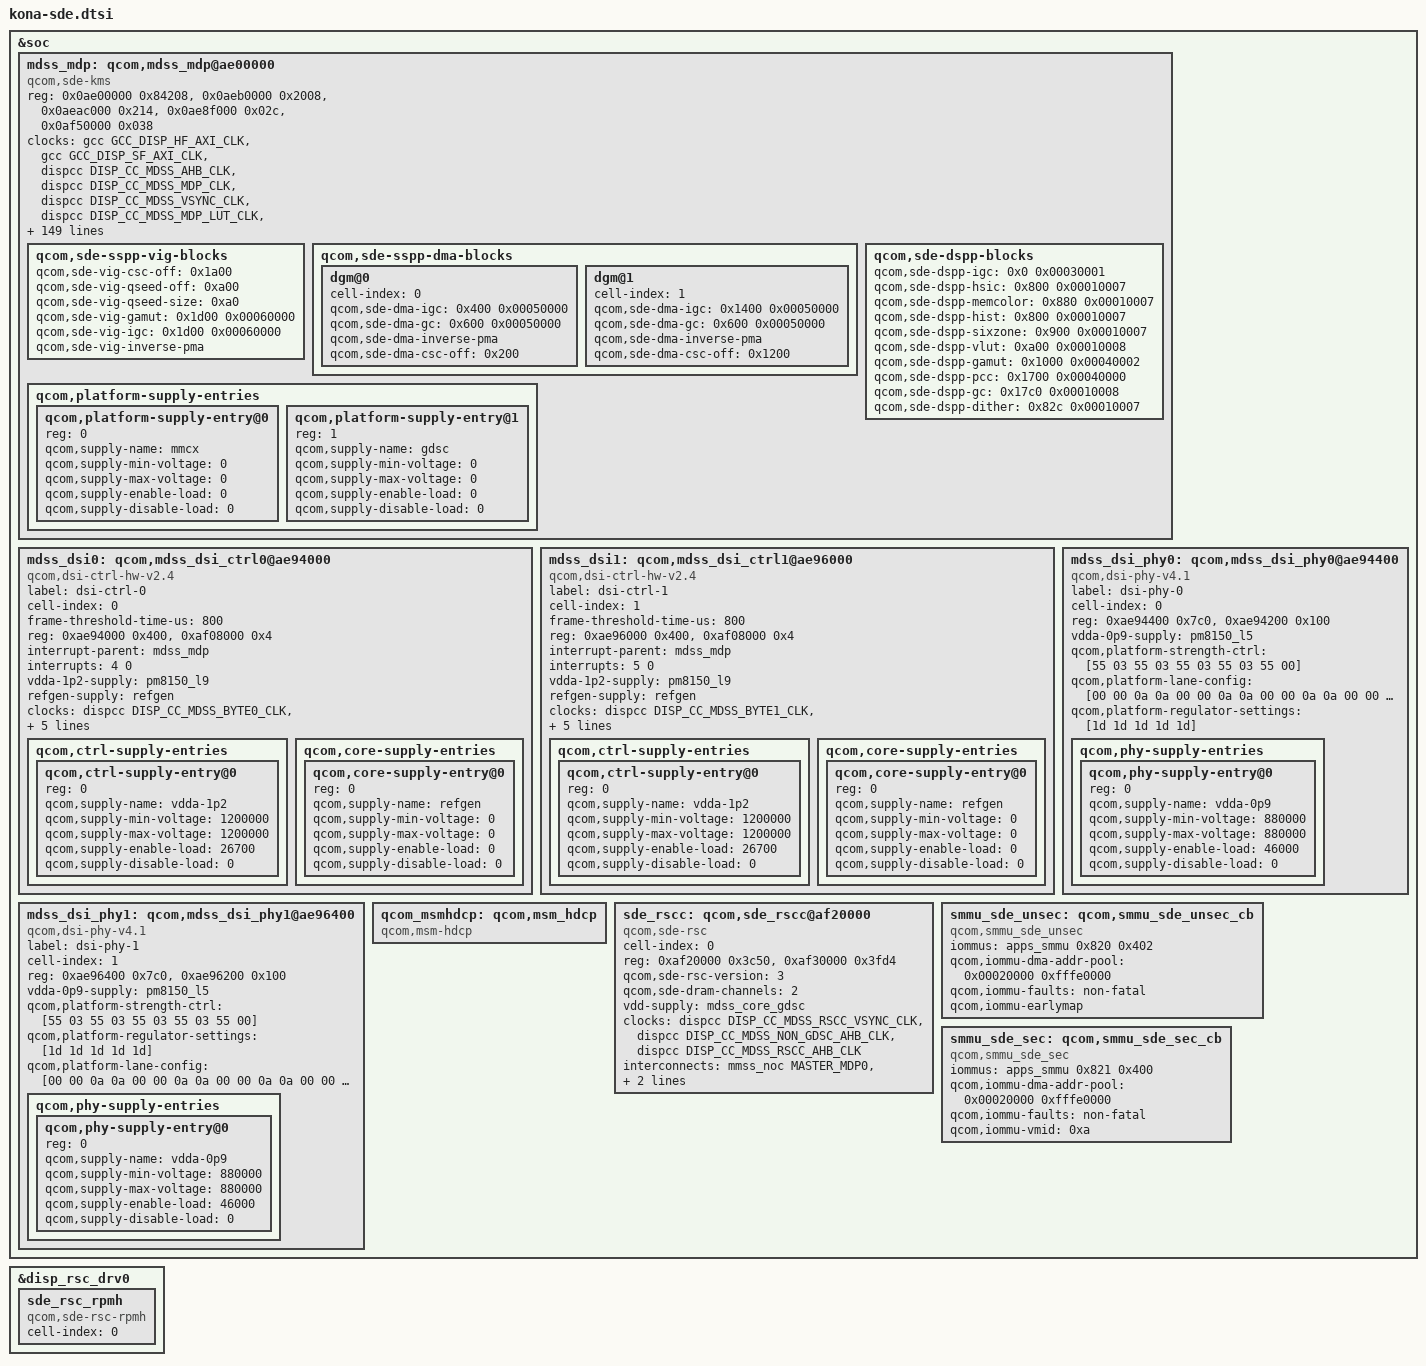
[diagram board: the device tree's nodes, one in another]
// SPDX-License-Identifier: GPL-2.0-only
/*
 * Kona (SM8250) MDSS/SDE controller nodes for the msm-5.15 display
 * techpack.  Hardware values (register offsets/sizes, block topology,
 * xin-ids, ...) are carried over from the 4.19 LG kona tree; the
 * property *names* follow the msm-5.15 SDE bindings.
 *
 * qcom,sde-hw-version is set explicitly to SDE_HW_VER(6,0,0) (kona,
 * SDE 6.0.0) so the catalog picks the IS_KONA_TARGET branch instead of
 * relying on socinfo.
 */

#include <dt-bindings/clock/qcom,rpmh.h>
#include <dt-bindings/clock/qcom,gcc-sm8250.h>
#include <dt-bindings/clock/qcom,dispcc-sm8250.h>
#include <dt-bindings/interrupt-controller/irq.h>
#include <dt-bindings/interconnect/qcom,kona.h>
#include <dt-bindings/regulator/qcom,rpmh-regulator-levels.h>

&soc {
	mdss_mdp: qcom,mdss_mdp@ae00000 {
		compatible = "qcom,sde-kms";
		reg = <0x0ae00000 0x84208>,
		      <0x0aeb0000 0x2008>,
		      <0x0aeac000 0x214>,
		      <0x0ae8f000 0x02c>,
		      <0x0af50000 0x038>;
		reg-names = "mdp_phys",
			"vbif_phys",
			"regdma_phys",
			"sid_phys",
			"swfuse_phys";

		/*
		 * msm-5.15 gcc-sm8250 no longer registers GCC_DISP_AHB_CLK;
		 * gcc_sm8250_probe() force-enables that branch in hardware and
		 * the clock is not exposed to consumers.  The 4.19 "gcc_iface"
		 * entry therefore has no handle in 5.15 and made
		 * sde_power_resource_init() fail with "clock set rate failed".
		 * The HF/SF AXI branches still exist.
		 */
		clocks =
			<&gcc GCC_DISP_HF_AXI_CLK>,
			<&gcc GCC_DISP_SF_AXI_CLK>,
			<&dispcc DISP_CC_MDSS_AHB_CLK>,
			<&dispcc DISP_CC_MDSS_MDP_CLK>,
			<&dispcc DISP_CC_MDSS_VSYNC_CLK>,
			<&dispcc DISP_CC_MDSS_MDP_LUT_CLK>,
			<&dispcc DISP_CC_MDSS_ROT_CLK>;
		clock-names = "gcc_bus", "gcc_nrt_bus",
				"iface_clk", "core_clk", "vsync_clk",
				"lut_clk", "rot_clk";
		clock-rate = <0 0 0 300000000 19200000 300000000 19200000>;
		clock-max-rate = <0 0 0 460000000 19200000 460000000
					460000000>;

		gdsc-supply = <&mdss_core_gdsc>;
		mmcx-supply = <&VDD_MMCX_LEVEL>;

		/* interrupt config */
		interrupts = <0 83 IRQ_TYPE_LEVEL_HIGH>;
		interrupt-controller;
		#interrupt-cells = <1>;
		/* msm-5.15 sde_connector_backlight_setup()/mi_disp expect a
		 * thermal cooling device on the mdss node; without this the
		 * backlight registration fails with -ENODEV and the DSI
		 * connector init is aborted.
		 */
		#cooling-cells = <2>;

		#address-cells = <1>;
		#size-cells = <0>;

		#power-domain-cells = <0>;

		/* hw blocks */
		qcom,sde-off = <0x1000>;
		qcom,sde-len = <0x494>;

		qcom,sde-hw-version = <0x60000000>;

		qcom,sde-ctl-off = <0x2000 0x2200 0x2400
				     0x2600 0x2800 0x2a00>;
		qcom,sde-ctl-size = <0x1dc>;
		qcom,sde-ctl-display-pref = "primary", "none", "none",
			    "none", "none";

		qcom,sde-mixer-off = <0x45000 0x46000 0x47000
				      0x48000 0x49000 0x4a000>;
		qcom,sde-mixer-size = <0x320>;
		qcom,sde-mixer-display-pref = "primary", "primary", "none",
					      "none", "none", "none";

		qcom,sde-mixer-cwb-pref = "none", "none", "cwb",
					      "cwb", "cwb", "cwb";

		qcom,sde-dspp-top-off = <0x1300>;
		qcom,sde-dspp-top-size = <0x80>;
		qcom,sde-dspp-off = <0x55000 0x57000 0x59000 0x5b000>;
		qcom,sde-dspp-size = <0x1800>;

		qcom,sde-dest-scaler-top-off = <0x00061000>;
		qcom,sde-dest-scaler-top-size = <0x1c>;
		qcom,sde-dest-scaler-off = <0x800 0x1000>;
		qcom,sde-dest-scaler-size = <0x800>;

		qcom,sde-wb-off = <0x66000>;
		qcom,sde-wb-size = <0x2c8>;
		qcom,sde-wb-xin-id = <6>;
		qcom,sde-wb-id = <2>;
		qcom,sde-wb-clk-ctrl = <0x2bc 16>;
		qcom,sde-wb-clk-status = <0x3bc 20>;

		qcom,sde-intf-off = <0x6b000 0x6b800
					0x6c000 0x6c800>;
		qcom,sde-intf-size = <0x2b8>;
		qcom,sde-intf-type = "dp", "dsi", "dsi", "dp";

		/*
		 * Tear-check interrupt blocks.  msm-4.19's kona catalog set
		 * SDE_INTF_TE unconditionally for hw 5.x/6.x and hardcoded
		 * these two offsets (MDP_INTF_TEAR_INTF_1/2_IRQ_OFF in
		 * sde_hw_interrupts.c), so command-mode panels got their
		 * rd_ptr/wr_ptr IRQs from the INTF tear block.  The 5.15
		 * catalog is DT-driven: without this property
		 * intf->te_irq_offset stays 0, SDE_INTF_TE is never set,
		 * phys_enc->has_intf_te = false, and cmd mode ends up
		 * polling the ping-pong block that kona does not implement
		 * as a tear source -> wr_ptr_irq/pingpong timeouts and no
		 * frame ever completes.  Index order follows
		 * qcom,sde-intf-type (dp, dsi, dsi, dp); 0 = no tear block.
		 */
		qcom,sde-intf-tear-irq-off = <0 0x6e800 0x6e900 0>;

		qcom,sde-pp-off = <0x71000 0x71800
					  0x72000 0x72800 0x73000 0x73800>;
		qcom,sde-pp-slave = <0x0 0x0 0x0 0x0 0x0 0x0>;
		qcom,sde-pp-size = <0xd4>;
		qcom,sde-pp-merge-3d-id = <0x0 0x0 0x1 0x1 0x2 0x2>;

		qcom,sde-merge-3d-off = <0x84000 0x84100 0x84200>;
		qcom,sde-merge-3d-size = <0x100>;

		qcom,sde-te2-off = <0x2000 0x2000 0x0 0x0 0x0 0x0>;

		qcom,sde-cdm-off = <0x7a200>;
		qcom,sde-cdm-size = <0x224>;

		qcom,sde-dsc-off = <0x81000 0x81400 0x81800 0x81c00>;
		qcom,sde-dsc-size = <0x140>;
		qcom,sde-dsc-pair-mask = <2 1 4 3>;
		qcom,sde-dsc-linewidth = <2048>;

		qcom,sde-dither-off = <0x30e0 0x30e0 0x30e0
							0x30e0 0x30e0 0x30e0>;
		qcom,sde-dither-version = <0x00010000>;
		qcom,sde-dither-size = <0x20>;

		qcom,sde-sspp-type = "vig", "vig", "vig", "vig",
					"dma", "dma", "dma", "dma";

		qcom,sde-sspp-off = <0x5000 0x7000 0x9000 0xb000
					0x25000 0x27000 0x29000 0x2b000>;
		qcom,sde-sspp-src-size = <0x1f8>;

		qcom,sde-sspp-xin-id = <0 4 8 12
					1 5 9 13>;
		qcom,sde-sspp-excl-rect = <1 1 1 1
						1 1 1 1>;
		qcom,sde-sspp-smart-dma-priority = <5 6 7 8 1 2 3 4>;
		qcom,sde-smart-dma-rev = "smart_dma_v2p5";

		qcom,sde-mixer-pair-mask = <2 1 4 3 6 5>;

		qcom,sde-mixer-blend-op-off = <0x20 0x38 0x50 0x68 0x80 0x98
						0xb0 0xc8 0xe0 0xf8 0x110>;

		qcom,sde-max-per-pipe-bw-kbps = <4400000 4400000
						 4400000 4400000
						 4400000 4400000
						 4400000 4400000>;

		qcom,sde-max-per-pipe-bw-high-kbps = <5300000 5300000
						      5300000 5300000
						      5300000 5300000
						      5300000 5300000>;

		/* offsets are relative to "mdp_phys + qcom,sde-off */
		qcom,sde-sspp-clk-ctrl =
				<0x2ac 0>, <0x2b4 0>, <0x2bc 0>, <0x2c4 0>,
				 <0x2ac 8>, <0x2b4 8>, <0x2bc 8>, <0x2c4 8>;
		qcom,sde-sspp-csc-off = <0x1a00>;
		qcom,sde-csc-type = "csc-10bit";
		qcom,sde-qseed-sw-lib-rev = "qseedv3lite";
		qcom,sde-qseed-scalar-version = <0x3000>;
		qcom,sde-sspp-qseed-off = <0xa00>;
		qcom,sde-mixer-linewidth = <2560>;
		qcom,sde-sspp-linewidth = <4096>;
		qcom,sde-wb-linewidth = <4096>;
		qcom,sde-mixer-blendstages = <0xb>;
		qcom,sde-highest-bank-bit = <0x3>;
		qcom,sde-ubwc-version = <0x40000000>;
		qcom,sde-ubwc-swizzle = <0x6>;
		qcom,sde-ubwc-bw-calc-version = <0x1>;
		qcom,sde-ubwc-static = <0x1>;
		qcom,sde-macrotile-mode = <0x1>;
		qcom,sde-smart-panel-align-mode = <0xc>;
		qcom,sde-panic-per-pipe;
		qcom,sde-has-src-split;
		qcom,sde-pipe-order-version = <0x1>;
		qcom,sde-has-dim-layer;
		qcom,sde-has-dest-scaler;
		qcom,sde-has-idle-pc;
		qcom,sde-max-dest-scaler-input-linewidth = <2048>;
		qcom,sde-max-dest-scaler-output-linewidth = <2560>;
		qcom,sde-max-bw-low-kbps = <13700000>;
		qcom,sde-max-bw-high-kbps = <16600000>;
		qcom,sde-min-core-ib-kbps = <4800000>;
		qcom,sde-min-llcc-ib-kbps = <0>;
		qcom,sde-min-dram-ib-kbps = <800000>;
		qcom,sde-dspp-ltm-version = <0x00010000>;
		/* offsets are based off dspp 0 and dspp 1 */
		qcom,sde-dspp-ltm-off = <0x2a000 0x28100>;

		qcom,sde-uidle-off = <0x80000>;
		qcom,sde-uidle-size = <0x70>;

		qcom,sde-vbif-off = <0>;
		qcom,sde-vbif-size = <0x1040>;
		qcom,sde-vbif-id = <0>;
		qcom,sde-vbif-memtype-0 = <3 3 3 3 3 3 3 3>;
		qcom,sde-vbif-memtype-1 = <3 3 3 3 3 3>;

		qcom,sde-vbif-qos-rt-remap = <3 3 4 4 5 5 6 6>;
		qcom,sde-vbif-qos-nrt-remap = <3 3 3 3 3 3 3 3>;
		qcom,sde-vbif-qos-cwb-remap = <3 3 4 4 5 5 6 3>;
		qcom,sde-vbif-qos-lutdma-remap = <3 3 3 3 4 4 4 4>;

		qcom,sde-cdp-setting = <1 1>, <1 0>;

		qcom,sde-qos-cpu-mask = <0x3>;
		qcom,sde-qos-cpu-mask-performance = <0xf>;
		qcom,sde-qos-cpu-dma-latency = <300>;
		qcom,sde-qos-cpu-irq-latency = <300>;

		/* offsets are relative to "mdp_phys + qcom,sde-off */
		qcom,sde-reg-dma-off = <0>;
		qcom,sde-reg-dma-version = <0x00010002>;
		qcom,sde-reg-dma-trigger-off = <0x119c>;
		qcom,sde-reg-dma-xin-id = <7>;
		qcom,sde-reg-dma-clk-ctrl = <0x2bc 20>;

		qcom,sde-secure-sid-mask = <0x4000821>;

		/* data and reg bus scale settings */
		interconnects =
			<&mmss_noc MASTER_MDP0 &mc_virt SLAVE_EBI1>,
			<&mmss_noc MASTER_MDP1 &mc_virt SLAVE_EBI1>,
			<&gem_noc MASTER_APPSS_PROC
				&config_noc SLAVE_DISPLAY_CFG>;
		interconnect-names = "qcom,sde-data-bus0", "qcom,sde-data-bus1",
			"qcom,sde-reg-bus";

		qcom,sde-ib-bw-vote = <2500000 0 800000>;

		/*
		 * msm-5.15 still requires the legacy reg-bus vote table even
		 * though the reg bus itself is voted through interconnects.
		 * Values are kona's 4.19 mdss_reg table in (ab, ib) form:
		 * disabled / low / medium / high.
		 */
		qcom,sde-reg-bus,vectors-KBps = <0 0>,
				<0 76800>,
				<0 150000>,
				<0 300000>;

		qcom,sde-sspp-vig-blocks {
			qcom,sde-vig-csc-off = <0x1a00>;
			qcom,sde-vig-qseed-off = <0xa00>;
			qcom,sde-vig-qseed-size = <0xa0>;
			qcom,sde-vig-gamut = <0x1d00 0x00060000>;
			qcom,sde-vig-igc = <0x1d00 0x00060000>;
			qcom,sde-vig-inverse-pma;
		};

		qcom,sde-sspp-dma-blocks {
			dgm@0 {
				cell-index = <0>;
				qcom,sde-dma-igc = <0x400 0x00050000>;
				qcom,sde-dma-gc = <0x600 0x00050000>;
				qcom,sde-dma-inverse-pma;
				qcom,sde-dma-csc-off = <0x200>;
			};

			dgm@1 {
				cell-index = <1>;
				qcom,sde-dma-igc = <0x1400 0x00050000>;
				qcom,sde-dma-gc = <0x600 0x00050000>;
				qcom,sde-dma-inverse-pma;
				qcom,sde-dma-csc-off = <0x1200>;
			};
		};

		qcom,sde-dspp-blocks {
			qcom,sde-dspp-igc = <0x0 0x00030001>;
			qcom,sde-dspp-hsic = <0x800 0x00010007>;
			qcom,sde-dspp-memcolor = <0x880 0x00010007>;
			qcom,sde-dspp-hist = <0x800 0x00010007>;
			qcom,sde-dspp-sixzone= <0x900 0x00010007>;
			qcom,sde-dspp-vlut = <0xa00 0x00010008>;
			qcom,sde-dspp-gamut = <0x1000 0x00040002>;
			qcom,sde-dspp-pcc = <0x1700 0x00040000>;
			qcom,sde-dspp-gc = <0x17c0 0x00010008>;
			qcom,sde-dspp-dither = <0x82c 0x00010007>;
		};

		qcom,platform-supply-entries {
			#address-cells = <1>;
			#size-cells = <0>;

			qcom,platform-supply-entry@0 {
				reg = <0>;
				qcom,supply-name = "mmcx";
				qcom,supply-min-voltage = <0>;
				qcom,supply-max-voltage = <0>;
				qcom,supply-enable-load = <0>;
				qcom,supply-disable-load = <0>;
			};

			/*
			 * msm-5.15 gdsc-regulator registers mdss_core_gdsc as a
			 * regulator and relies on a proxy consumer that is torn
			 * down by late_initcall_sync(regulator_proxy_consumer_remove_all).
			 * The display power handle must therefore hold a real
			 * reference, otherwise the GDSC is powered off at the end
			 * of late init while the MDP is still scanning out the
			 * cont-splash frame (SMMU fault at iova 0).
			 *
			 * The entry is named "gdsc" (not "sde-vdd") because
			 * msm_dss_is_hw_controlled() special-cases exactly that
			 * name: once the display RSC has handed the GDSC over to
			 * its hardware trigger (REGULATOR_MODE_FAST) the MDP must
			 * not enable/disable it itself, otherwise gdsc_enable()
			 * fails with -EBUSY ("Invalid enable while ... is under HW
			 * control") and the failed power-up is followed by
			 * register writes to an unpowered MDP (SError panic).
			 */
			qcom,platform-supply-entry@1 {
				reg = <1>;
				qcom,supply-name = "gdsc";
				qcom,supply-min-voltage = <0>;
				qcom,supply-max-voltage = <0>;
				qcom,supply-enable-load = <0>;
				qcom,supply-disable-load = <0>;
			};
		};
	};

	mdss_dsi0: qcom,mdss_dsi_ctrl0@ae94000 {
		compatible = "qcom,dsi-ctrl-hw-v2.4";
		label = "dsi-ctrl-0";
		cell-index = <0>;
		frame-threshold-time-us = <800>;
		reg = <0xae94000 0x400>,
			<0xaf08000 0x4>;
		reg-names = "dsi_ctrl", "disp_cc_base";
		interrupt-parent = <&mdss_mdp>;
		interrupts = <4 0>;
		vdda-1p2-supply = <&pm8150_l9>;
		refgen-supply = <&refgen>;
		clocks = <&dispcc DISP_CC_MDSS_BYTE0_CLK>,
			<&dispcc DISP_CC_MDSS_BYTE0_CLK_SRC>,
			<&dispcc DISP_CC_MDSS_BYTE0_INTF_CLK>,
			<&dispcc DISP_CC_MDSS_PCLK0_CLK>,
			<&dispcc DISP_CC_MDSS_PCLK0_CLK_SRC>,
			<&dispcc DISP_CC_MDSS_ESC0_CLK>;
		clock-names = "byte_clk", "byte_clk_rcg", "byte_intf_clk",
				"pixel_clk", "pixel_clk_rcg", "esc_clk";

		qcom,ctrl-supply-entries {
			#address-cells = <1>;
			#size-cells = <0>;

			qcom,ctrl-supply-entry@0 {
				reg = <0>;
				qcom,supply-name = "vdda-1p2";
				qcom,supply-min-voltage = <1200000>;
				qcom,supply-max-voltage = <1200000>;
				qcom,supply-enable-load = <26700>;
				qcom,supply-disable-load = <0>;
			};
		};

		qcom,core-supply-entries {
			#address-cells = <1>;
			#size-cells = <0>;

			qcom,core-supply-entry@0 {
				reg = <0>;
				qcom,supply-name = "refgen";
				qcom,supply-min-voltage = <0>;
				qcom,supply-max-voltage = <0>;
				qcom,supply-enable-load = <0>;
				qcom,supply-disable-load = <0>;
			};
		};
	};

	mdss_dsi1: qcom,mdss_dsi_ctrl1@ae96000 {
		compatible = "qcom,dsi-ctrl-hw-v2.4";
		label = "dsi-ctrl-1";
		cell-index = <1>;
		frame-threshold-time-us = <800>;
		reg = <0xae96000 0x400>,
			<0xaf08000 0x4>;
		reg-names = "dsi_ctrl", "disp_cc_base";
		interrupt-parent = <&mdss_mdp>;
		interrupts = <5 0>;
		vdda-1p2-supply = <&pm8150_l9>;
		refgen-supply = <&refgen>;
		clocks = <&dispcc DISP_CC_MDSS_BYTE1_CLK>,
			<&dispcc DISP_CC_MDSS_BYTE1_CLK_SRC>,
			<&dispcc DISP_CC_MDSS_BYTE1_INTF_CLK>,
			<&dispcc DISP_CC_MDSS_PCLK1_CLK>,
			<&dispcc DISP_CC_MDSS_PCLK1_CLK_SRC>,
			<&dispcc DISP_CC_MDSS_ESC1_CLK>;
		clock-names = "byte_clk", "byte_clk_rcg", "byte_intf_clk",
				"pixel_clk", "pixel_clk_rcg", "esc_clk";

		qcom,ctrl-supply-entries {
			#address-cells = <1>;
			#size-cells = <0>;

			qcom,ctrl-supply-entry@0 {
				reg = <0>;
				qcom,supply-name = "vdda-1p2";
				qcom,supply-min-voltage = <1200000>;
				qcom,supply-max-voltage = <1200000>;
				qcom,supply-enable-load = <26700>;
				qcom,supply-disable-load = <0>;
			};
		};

		qcom,core-supply-entries {
			#address-cells = <1>;
			#size-cells = <0>;

			qcom,core-supply-entry@0 {
				reg = <0>;
				qcom,supply-name = "refgen";
				qcom,supply-min-voltage = <0>;
				qcom,supply-max-voltage = <0>;
				qcom,supply-enable-load = <0>;
				qcom,supply-disable-load = <0>;
			};
		};
	};

	mdss_dsi_phy0: qcom,mdss_dsi_phy0@ae94400 {
		compatible = "qcom,dsi-phy-v4.1";
		label = "dsi-phy-0";
		cell-index = <0>;
		/*
		 * No pll-label / pll_base: the PLL is the standalone
		 * mdss_dsi0_pll node (kona-sde-pll.dtsi), not integrated
		 * into the PHY as in the default 5.15 techpack.
		 */
		reg = <0xae94400 0x7c0>,
			<0xae94200 0x100>;
		reg-names = "dsi_phy", "dyn_refresh_base";
		vdda-0p9-supply = <&pm8150_l5>;
		qcom,platform-strength-ctrl = [55 03
						55 03
						55 03
						55 03
						55 00];
		qcom,platform-lane-config = [00 00 0a 0a
						00 00 0a 0a
						00 00 0a 0a
						00 00 0a 0a
						00 00 8a 8a];
		qcom,platform-regulator-settings = [1d 1d 1d 1d 1d];
		qcom,phy-supply-entries {
			#address-cells = <1>;
			#size-cells = <0>;
			qcom,phy-supply-entry@0 {
				reg = <0>;
				qcom,supply-name = "vdda-0p9";
				qcom,supply-min-voltage = <880000>;
				qcom,supply-max-voltage = <880000>;
				qcom,supply-enable-load = <46000>;
				qcom,supply-disable-load = <0>;
			};
		};
	};

	mdss_dsi_phy1: qcom,mdss_dsi_phy1@ae96400 {
		compatible = "qcom,dsi-phy-v4.1";
		label = "dsi-phy-1";
		cell-index = <1>;
		reg = <0xae96400 0x7c0>,
			<0xae96200 0x100>;
		reg-names = "dsi_phy", "dyn_refresh_base";
		vdda-0p9-supply = <&pm8150_l5>;
		qcom,platform-strength-ctrl = [55 03
						55 03
						55 03
						55 03
						55 00];
		qcom,platform-regulator-settings = [1d 1d 1d 1d 1d];
		qcom,platform-lane-config = [00 00 0a 0a
						00 00 0a 0a
						00 00 0a 0a
						00 00 0a 0a
						00 00 8a 8a];
		qcom,phy-supply-entries {
			#address-cells = <1>;
			#size-cells = <0>;
			qcom,phy-supply-entry@0 {
				reg = <0>;
				qcom,supply-name = "vdda-0p9";
				qcom,supply-min-voltage = <880000>;
				qcom,supply-max-voltage = <880000>;
				qcom,supply-enable-load = <46000>;
				qcom,supply-disable-load = <0>;
			};
		};
	};

	qcom_msmhdcp: qcom,msm_hdcp {
		compatible = "qcom,msm-hdcp";
	};

	sde_rscc: qcom,sde_rscc@af20000 {
		cell-index = <0>;
		compatible = "qcom,sde-rsc";
		reg = <0xaf20000 0x3c50>,
			<0xaf30000 0x3fd4>;
		reg-names = "drv", "wrapper";
		qcom,sde-rsc-version = <3>;

		qcom,sde-dram-channels = <2>;

		/*
		 * sde_rsc.c does devm_regulator_get(dev, "vdd") + regulator_enable()
		 * for the lifetime of the display driver, and sde_rsc_mode2_entry()
		 * flips it to REGULATOR_MODE_FAST (hw trigger).  Pointing it at
		 * mdss_core_gdsc therefore (a) gives the GDSC a permanent real
		 * reference so the proxy-consumer teardown at late_initcall_sync
		 * cannot power it off under the cont-splash frame, and (b) makes
		 * msm_dss_is_hw_controlled() skip the MDP's own "gdsc" supply
		 * entry once the RSC owns the rail.
		 */
		vdd-supply = <&mdss_core_gdsc>;
		clocks = <&dispcc DISP_CC_MDSS_RSCC_VSYNC_CLK>,
			<&dispcc DISP_CC_MDSS_NON_GDSC_AHB_CLK>,
			<&dispcc DISP_CC_MDSS_RSCC_AHB_CLK>;
		clock-names = "vsync_clk", "gdsc_clk", "iface_clk";

		interconnects =
			<&mmss_noc MASTER_MDP0 &mc_virt SLAVE_EBI1>,
			<&mmss_noc MASTER_MDP1 &mc_virt SLAVE_EBI1>;
		interconnect-names = "qcom,sde-data-bus0", "qcom,sde-data-bus1";
	};

	smmu_sde_unsec: qcom,smmu_sde_unsec_cb {
		compatible = "qcom,smmu_sde_unsec";
		iommus = <&apps_smmu 0x820 0x402>;
		qcom,iommu-dma-addr-pool = <0x00020000 0xfffe0000>;
		qcom,iommu-faults = "non-fatal";
		qcom,iommu-earlymap; /* for cont-splash */
	};

	smmu_sde_sec: qcom,smmu_sde_sec_cb {
		compatible = "qcom,smmu_sde_sec";
		iommus = <&apps_smmu 0x821 0x400>;
		qcom,iommu-dma-addr-pool = <0x00020000 0xfffe0000>;
		qcom,iommu-faults = "non-fatal";
		qcom,iommu-vmid = <0xa>;
	};
};

/*
 * msm-5.15 sde_rsc.c splits the display RSC in two platform devices: the
 * "qcom,sde-rsc" node (sde_rscc@af20000) and a "qcom,sde-rsc-rpmh" child
 * that only publishes the RPMh device in sde_rsc.c:rpmh_dev[].  The RSC
 * probe looks it up and fails hard (-EINVAL, no deferred retry) when it
 * is missing, which leaves mdss_mdp/DSI deferring forever.  The 4.19
 * kernel had no such child node because its driver got the RPMh device
 * differently.
 */
&disp_rsc_drv0 {
	sde_rsc_rpmh {
		compatible = "qcom,sde-rsc-rpmh";
		cell-index = <0>;
	};
};
